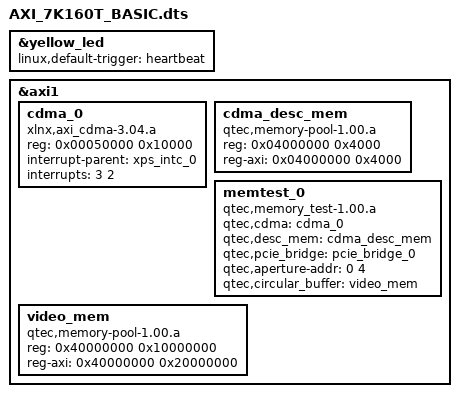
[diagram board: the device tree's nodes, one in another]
/dts-v1/;

/include/ "qt5046.dtsi"

&yellow_led {
	linux,default-trigger = "heartbeat";
};

&axi1 {

	cdma_0: cdma_0{
		#address-cells = <1>;
		#size-cells = <1>;
	     	compatible = "xlnx,axi_cdma-3.04.a";
		reg = < 0x00050000 0x10000 >;
		interrupt-parent = <&xps_intc_0>;
		interrupts = < 3 2 >;

	};

	cdma_desc_mem: cdma_desc_mem {
		#address-cells = <1>;
		#size-cells = <1>;
	     	compatible = "qtec,memory-pool-1.00.a";
		reg = < 0x04000000 0x4000 >;
		reg-axi = < 0x04000000 0x4000 >;
	};

	memtest_0: memtest_0{
		#address-cells = <1>;
		#size-cells = <1>;
	     	compatible = "qtec,memory_test-1.00.a";
		qtec,cdma = <&cdma_0>;
		qtec,desc_mem= <&cdma_desc_mem>;
		qtec,pcie_bridge= <&pcie_bridge_0>;
		qtec,aperture-addr= < 0  4 >;
		qtec,circular_buffer= <&video_mem>;
	};

	video_mem: video_mem {
		#address-cells = <1>;
		#size-cells = <1>;
	     	compatible = "qtec,memory-pool-1.00.a";
		reg = < 0x40000000 0x10000000 >;
		reg-axi = < 0x40000000 0x20000000>; //Duplicated
	};


};
